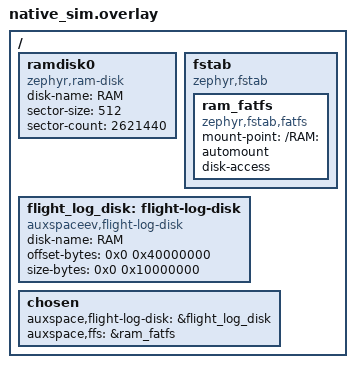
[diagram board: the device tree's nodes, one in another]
/*
 * Copyright (c) 2026 Auxspace e.V.
 * SPDX-License-Identifier: Apache-2.0
 *
 * RAM disk (64 KiB) with an auto-mounted FatFS volume for the data
 * logger formatter tests.  Zephyr's fstab init hook mounts the volume
 * before any test suite runs, so no explicit fs_mount() is needed.
 *
 * A 1 MiB partition is also carved out of the simulated flash for the
 * raw-flash flight log (no filesystem).  The base sim-flash partition
 * layout uses 0x000000–0x100000; the trailing 1 MiB is unused, so we
 * place the flight log at 0x100000 and use the full slice so circular
 * mode has a comfortable pre-boost ring during ground tests.
 */

/ {
	ramdisk0 {
		compatible = "zephyr,ram-disk";
		disk-name = "RAM";
		sector-size = <512>;
		sector-count = <2621440>;	/* 1 GiB + 256 MiB */
	};

	fstab {
		compatible = "zephyr,fstab";

		ram_fatfs: ram_fatfs {
			compatible = "zephyr,fstab,fatfs";
			mount-point = "/RAM:";
			automount;
			disk-access;
		};
	};

	flight_log_disk: flight-log-disk {
		compatible = "auxspaceev,flight-log-disk";
		disk-name = "RAM";
		offset-bytes = <0x0 0x40000000>;	/* 1 GiB */
		size-bytes   = <0x0 0x10000000>;	/* 256 MiB */
	};

	chosen {
		auxspace,flight-log-disk = &flight_log_disk;
		auxspace,ffs = &ram_fatfs;
	};
};
